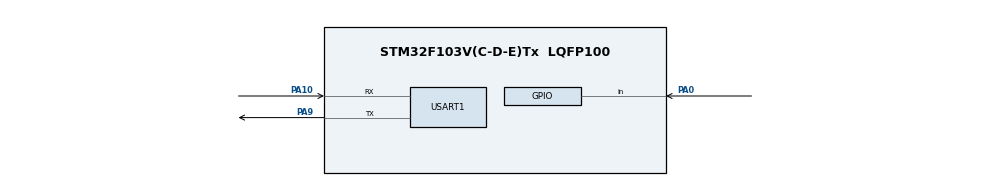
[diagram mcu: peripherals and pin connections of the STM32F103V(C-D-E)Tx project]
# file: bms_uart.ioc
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Mcu.Family=STM32F1
Mcu.Name=STM32F103V(C-D-E)Tx
Mcu.Package=LQFP100
NVIC.PriorityGroup=NVIC_PRIORITYGROUP_4
NVIC.USART1_IRQn=true\:0\:0\:false\:false\:true\:true\:true
PA0-WKUP.Signal=GPIO_Input
PA10.Mode=Asynchronous
PA10.Signal=USART1_RX
PA13.Mode=Serial_Wire
PA13.Signal=SYS_JTMS-SWDIO
PA14.Mode=Serial_Wire
PA14.Signal=SYS_JTCK-SWCLK
PA9.Mode=Asynchronous
PA9.Signal=USART1_TX
ProjectManager.HeapSize=0x200
ProjectManager.StackSize=0x400
ProjectManager.TargetToolchain=MDK-ARM V5.27
RCC.APB1Freq_Value=8000000
RCC.APB2Freq_Value=8000000
USART1.VirtualMode=VM_ASYNC
board=custom

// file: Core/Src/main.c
/* USER CODE BEGIN Header */
/**
  ******************************************************************************
  * @file           : main.c
  * @brief          : Main program body
  ******************************************************************************
  * @attention
  *
  * <h2><center>&copy; Copyright (c) 2021 STMicroelectronics.
  * All rights reserved.</center></h2>
  *
  * This software component is licensed by ST under BSD 3-Clause license,
  * the "License"; You may not use this file except in compliance with the
  * License. You may obtain a copy of the License at:
  *                        opensource.org/licenses/BSD-3-Clause
  *
  ******************************************************************************
  */
/* USER CODE END Header */
#include "main.h"
#include "usart.h"
#include "gpio.h"

/* USER CODE BEGIN Includes */
#include "bms_comm.h"
#include "stdio.h"
#include "stdarg.h"
#include "string.h"

/* USER CODE END Includes */

/* USER CODE BEGIN PD */
#define uart_len 255
#define uart_time 500

/* USER CODE END PD */

/* USER CODE BEGIN PV */
uint8_t rx_data[uart_len];
uint32_t uart_tmp_time;
uint8_t bms_cmd = 0x0f;
uint8_t bms_cmd_data = 0x00;
uint32_t tx_bms_time = 0;
extern uint8_t tx_count;
extern uint8_t rx_count;
extern uint8_t rx_buffer[uart_len];
/* USER CODE END PV */

void SystemClock_Config(void);

void ReadData(uint8_t ble_cmd, uint8_t ble_cmd_data);

void Tx_Meituan_Data(uint8_t ble_cmd, uint8_t ble_cmd_data);

void MyPrintf(const char *__format, ...);

int main(void)
{

    /* MCU Configuration--------------------------------------------------------*/

    /* Reset of all peripherals, Initializes the Flash interface and the Systick. */
    HAL_Init();

    /* Configure the system clock */
    SystemClock_Config();

    /* Initialize all configured peripherals */
    MX_GPIO_Init();
    MX_USART1_UART_Init();
    /* USER CODE BEGIN 2 */
    HAL_UART_Receive_IT(&huart1, rx_data, 1);
    /* USER CODE END 2 */

    /* Infinite loop */
    while (1)
    {

        ReadData(bms_cmd, bms_cmd_data);

        if(rx_count == 0 && tx_count == 0 && (HAL_GetTick() - tx_bms_time > 500))
        {
            if(bms_cmd == 0x19)
            {

							bms_cmd = 0x0f;
            }

            bms_cmd ++;

            if(bms_cmd == 0x12)
            {
                bms_cmd ++;
            }

            Tx_Meituan_Data(bms_cmd, bms_cmd_data);
            tx_bms_time = HAL_GetTick();
        }
        else
        {
            if(tx_count == 3)
            {
                tx_count = 0;

                if(bms_cmd == 0x19)
                {
                    bms_cmd = 0x0f;
                }
            }
        }

    }
}

void SystemClock_Config(void)
{
    RCC_OscInitTypeDef RCC_OscInitStruct = {0};
    RCC_ClkInitTypeDef RCC_ClkInitStruct = {0};

    /** Initializes the RCC Oscillators according to the specified parameters
    * in the RCC_OscInitTypeDef structure.
    */
    RCC_OscInitStruct.OscillatorType = RCC_OSCILLATORTYPE_HSI;
    RCC_OscInitStruct.HSIState = RCC_HSI_ON;
    RCC_OscInitStruct.HSICalibrationValue = RCC_HSICALIBRATION_DEFAULT;
    RCC_OscInitStruct.PLL.PLLState = RCC_PLL_NONE;

    if (HAL_RCC_OscConfig(&RCC_OscInitStruct) != HAL_OK)
    {
        Error_Handler();
    }

    /** Initializes the CPU, AHB and APB buses clocks
    */
    RCC_ClkInitStruct.ClockType = RCC_CLOCKTYPE_HCLK | RCC_CLOCKTYPE_SYSCLK
                                  | RCC_CLOCKTYPE_PCLK1 | RCC_CLOCKTYPE_PCLK2;
    RCC_ClkInitStruct.SYSCLKSource = RCC_SYSCLKSOURCE_HSI;
    RCC_ClkInitStruct.AHBCLKDivider = RCC_SYSCLK_DIV1;
    RCC_ClkInitStruct.APB1CLKDivider = RCC_HCLK_DIV1;
    RCC_ClkInitStruct.APB2CLKDivider = RCC_HCLK_DIV1;

    if (HAL_RCC_ClockConfig(&RCC_ClkInitStruct, FLASH_LATENCY_0) != HAL_OK)
    {
        Error_Handler();
    }
}

void Error_Handler(void)
{
    __disable_irq();
    while (1)
    {
    }
}

/************************ (C) COPYRIGHT STMicroelectronics *****END OF FILE****/
